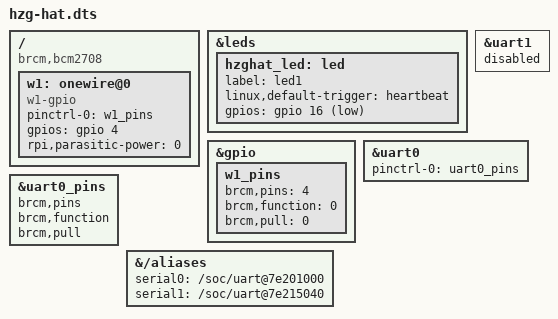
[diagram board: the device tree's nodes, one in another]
/dts-v1/;
/plugin/;

/ {
  compatible = "brcm,bcm2708";

  fragment@0 {
    target = <&leds>;
    __overlay__ {
      hzghat_led: led {
        label = "led1";
        linux,default-trigger = "heartbeat";
        gpios = <&gpio 16 1>;
      };
    };
  };

// from w1-gpio.dts, activate 1wire

	fragment@1 {
		target-path = "/";
		__overlay__ {

			w1: onewire@0 {
				compatible = "w1-gpio";
				pinctrl-names = "default";
				pinctrl-0 = <&w1_pins>;
				gpios = <&gpio 4 0>;
				rpi,parasitic-power = <0>;
				status = "okay";
			};
		};
	};

	fragment@2 {
		target = <&gpio>;
		__overlay__ {
			w1_pins: w1_pins {
				brcm,pins = <4>;
				brcm,function = <0>; // in (initially)
				brcm,pull = <0>; // off
			};
		};
	};

	fragment@3 {
		target = <&uart1>;
		__overlay__ {
			status = "disabled";
		};
	};

	fragment@4 {
		target = <&uart0>;
		__overlay__ {
			pinctrl-names = "default";
			pinctrl-0 = <&uart0_pins>;
			status = "okay";
		};
	};

	fragment@5 {
		target = <&uart0_pins>;
		__overlay__ {
			brcm,pins;
			brcm,function;
			brcm,pull;
		};
	};

	fragment@6 {
		target-path = "/aliases";
		__overlay__ {
			serial0 = "/soc/uart@7e201000";
			serial1 = "/soc/uart@7e215040";
		};
	};

	__overrides__ {
		hzghat_gpio =       <&hzghat_led>,"gpios:4";
		hzghat_activelow =  <&hzghat_led>,"gpios:8";
		hzghat__trigger =   <&hzghat_led>,"linux,default-trigger";
		gpiopin =           <&w1>,"gpios:4",
				    <&w1_pins>,"brcm,pins:0";
		pullup =            <&w1>,"rpi,parasitic-power:0";
	};
};
